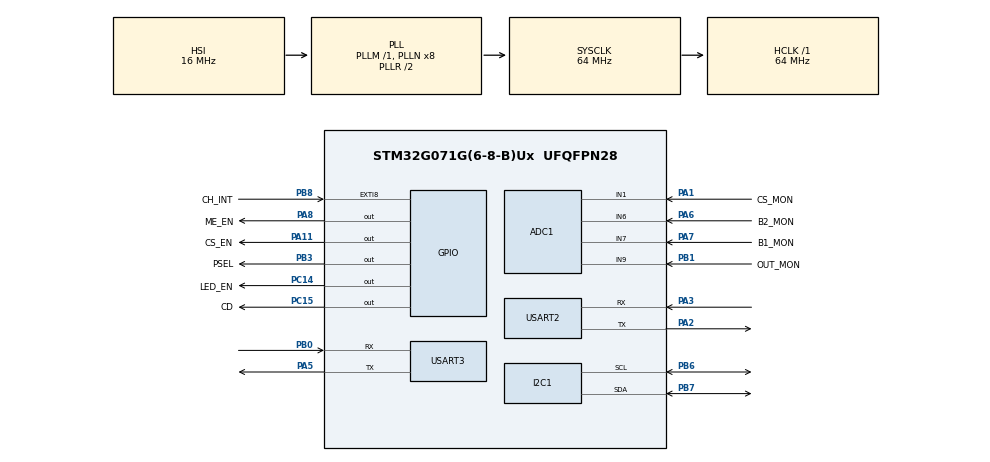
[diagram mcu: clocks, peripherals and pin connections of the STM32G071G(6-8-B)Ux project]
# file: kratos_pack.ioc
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ADC1.Channel-0\#ChannelRegularConversion=ADC_CHANNEL_6
ADC1.NbrOfConversionFlag=1
ADC1.Rank-0\#ChannelRegularConversion=1
ADC1.SamplingTime-0\#ChannelRegularConversion=ADC_SAMPLINGTIME_COMMON_1
ADC1.SelectedChannel=ADC_CHANNEL_1|ADC_CHANNEL_6|ADC_CHANNEL_7|ADC_CHANNEL_9|ADC_CHANNEL_TEMPSENSOR|ADC_CHANNEL_VREFINT
ADC1.master=1
I2C1.Timing=0x10707DBC
Mcu.Family=STM32G0
Mcu.Name=STM32G071G(6-8-B)Ux
Mcu.Package=UFQFPN28
NVIC.USART2_IRQn=true\:0\:0\:false\:false\:true\:true\:true
NVIC.USART3_4_LPUART1_IRQn=true\:0\:0\:false\:false\:true\:true\:true
PA0.GPIO_Label=BOOT
PA0.Mode=SYS_WakeUp0
PA0.Signal=SYS_WKUP1
PA1.GPIO_Label=CS_MON
PA1.Mode=IN1
PA1.Signal=ADC1_IN1
PA11\ [PA9].GPIO_Label=CS_EN
PA11\ [PA9].Signal=GPIO_Output
PA13.Mode=Serial_Wire
PA13.Signal=SYS_SWDIO
PA14-BOOT0.Mode=Serial_Wire
PA14-BOOT0.Signal=SYS_SWCLK
PA2.Mode=Asynchronous
PA2.Signal=USART2_TX
PA3.Mode=Asynchronous
PA3.Signal=USART2_RX
PA4.GPIO_Label=WAKEUP
PA4.Mode=SYS_WakeUp1
PA4.Signal=SYS_WKUP2
PA5.Mode=Asynchronous
PA5.Signal=USART3_TX
PA6.GPIO_Label=B2_MON
PA6.Mode=IN6
PA6.Signal=ADC1_IN6
PA7.GPIO_Label=B1_MON
PA7.Mode=IN7
PA7.Signal=ADC1_IN7
PA8.GPIO_Label=ME_EN
PA8.Signal=GPIO_Output
PB0.Mode=Asynchronous
PB0.Signal=USART3_RX
PB1.GPIO_Label=OUT_MON
PB1.Mode=IN9
PB1.Signal=ADC1_IN9
PB3.GPIO_Label=PSEL
PB3.Signal=GPIO_Output
PB5.GPIO_Label=USD_DET
PB5.Mode=SYS_WakeUp6
PB5.Signal=SYS_WKUP6
PB6.Mode=I2C
PB6.Signal=I2C1_SCL
PB7.Mode=I2C
PB7.Signal=I2C1_SDA
PB8.GPIO_Label=CH_INT
PB8.Signal=GPXTI8
PC14-OSC32_IN\ (PC14).GPIO_Label=LED_EN
PC14-OSC32_IN\ (PC14).Signal=GPIO_Output
PC15-OSC32_OUT\ (PC15).GPIO_Label=CD
PC15-OSC32_OUT\ (PC15).Signal=GPIO_Output
ProjectManager.HeapSize=0x200
ProjectManager.StackSize=0x400
ProjectManager.TargetToolchain=Makefile
RCC.ADCFreq_Value=64000000
RCC.AHBFreq_Value=64000000
RCC.CortexFreq_Value=64000000
RCC.EXTERNAL_CLOCK_VALUE=48000
RCC.HCLKFreq_Value=64000000
RCC.HSE_VALUE=8000000
RCC.HSI_VALUE=16000000
RCC.LSE_VALUE=32768
RCC.SYSCLKFreq_VALUE=64000000
RCC.SYSCLKSource=RCC_SYSCLKSOURCE_PLLCLK
RCC.VCOOutputFreq_Value=128000000
USART2.VirtualMode-Asynchronous=VM_ASYNC
USART3.VirtualMode-Asynchronous=VM_ASYNC
VP_ADC1_TempSens_Input.Mode=IN-TempSens
VP_ADC1_Vref_Input.Mode=IN-Vrefint
VP_SYS_VS_DBSignals.Mode=DisableDeadBatterySignals
VP_TIM2_VS_ClockSourceINT.Mode=Internal
board=custom

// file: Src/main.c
/* USER CODE BEGIN Header */

/**
  ******************************************************************************
  * @file           : main.c
  * @brief          : Main program body
  ******************************************************************************
  * @attention
  *
  * <h2><center>&copy; Copyright (c) 2021 STMicroelectronics.
  * All rights reserved.</center></h2>
  *
  * This software component is licensed by ST under BSD 3-Clause license,
  * the "License"; You may not use this file except in compliance with the
  * License. You may obtain a copy of the License at:
  *                        opensource.org/licenses/BSD-3-Clause
  *
  ******************************************************************************
  */
/* USER CODE END Header */
#include "main.h"

/* USER CODE BEGIN Includes */
#include "stm32g0xx_hal.h"

#include "device/device.hpp"
#include "led/KTD2026.hpp"
#include "apps/i2c_scanner.hpp"
/* USER CODE END Includes */

ADC_HandleTypeDef hadc1;

I2C_HandleTypeDef hi2c1;

TIM_HandleTypeDef htim2;

UART_HandleTypeDef huart2;
UART_HandleTypeDef huart3;

void SystemClock_Config(void);
static void MX_GPIO_Init(void);
static void MX_I2C1_Init(void);
static void MX_USART2_UART_Init(void);
static void MX_USART3_UART_Init(void);
static void MX_ADC1_Init(void);
static void MX_TIM2_Init(void);

int main(void){

    /* MCU Configuration--------------------------------------------------------*/

    /* Reset of all peripherals, Initializes the Flash interface and the Systick. */
    HAL_Init();

    /* Configure the system clock */
    SystemClock_Config();

    /* Initialize all configured peripherals */
    MX_GPIO_Init();
    MX_I2C1_Init();
    MX_USART2_UART_Init();
    MX_USART3_UART_Init();
    MX_ADC1_Init();
    MX_TIM2_Init();
    /* USER CODE BEGIN 2 */
    HAL_Delay(1);

    device()->mcu->UART_2->Send("Hello world\r\n");

    device()->Enable_CLI(device()->mcu->UART_2);
    device()->Enable_Filesystem();
    device()->cli->Enable_filesystem_executable(device()->fs);

    auto app = new I2C_scanner(device()->mcu->I2C_1);

    auto led_enable = new Pin('C', 14);
    led_enable->Set(true);

    auto led = new KTD2026(*(device()->mcu->I2C_1), 0b01100010);
    led->Test();

    /* USER CODE END 2 */

    /* Infinite loop */
    while (1) {

    }
} // main

void SystemClock_Config(void){
    RCC_OscInitTypeDef RCC_OscInitStruct   = { 0 };
    RCC_ClkInitTypeDef RCC_ClkInitStruct   = { 0 };
    RCC_PeriphCLKInitTypeDef PeriphClkInit = { 0 };

    /** Configure the main internal regulator output voltage
    */
    HAL_PWREx_ControlVoltageScaling(PWR_REGULATOR_VOLTAGE_SCALE1);

    /** Initializes the RCC Oscillators according to the specified parameters
    * in the RCC_OscInitTypeDef structure.
    */
    RCC_OscInitStruct.OscillatorType      = RCC_OSCILLATORTYPE_HSI;
    RCC_OscInitStruct.HSIState            = RCC_HSI_ON;
    RCC_OscInitStruct.HSIDiv              = RCC_HSI_DIV1;
    RCC_OscInitStruct.HSICalibrationValue = RCC_HSICALIBRATION_DEFAULT;
    RCC_OscInitStruct.PLL.PLLState        = RCC_PLL_ON;
    RCC_OscInitStruct.PLL.PLLSource       = RCC_PLLSOURCE_HSI;
    RCC_OscInitStruct.PLL.PLLM            = RCC_PLLM_DIV1;
    RCC_OscInitStruct.PLL.PLLN            = 8;
    RCC_OscInitStruct.PLL.PLLP            = RCC_PLLP_DIV2;
    RCC_OscInitStruct.PLL.PLLQ            = RCC_PLLQ_DIV2;
    RCC_OscInitStruct.PLL.PLLR            = RCC_PLLR_DIV2;
    if (HAL_RCC_OscConfig(&RCC_OscInitStruct) != HAL_OK) {
        Error_Handler();
    }

    /** Initializes the CPU, AHB and APB buses clocks
    */
    RCC_ClkInitStruct.ClockType = RCC_CLOCKTYPE_HCLK | RCC_CLOCKTYPE_SYSCLK
      | RCC_CLOCKTYPE_PCLK1;
    RCC_ClkInitStruct.SYSCLKSource   = RCC_SYSCLKSOURCE_PLLCLK;
    RCC_ClkInitStruct.AHBCLKDivider  = RCC_SYSCLK_DIV1;
    RCC_ClkInitStruct.APB1CLKDivider = RCC_HCLK_DIV1;

    if (HAL_RCC_ClockConfig(&RCC_ClkInitStruct, FLASH_LATENCY_2) != HAL_OK) {
        Error_Handler();
    }

    /** Initializes the peripherals clocks
    */
    PeriphClkInit.PeriphClockSelection = RCC_PERIPHCLK_USART2 | RCC_PERIPHCLK_I2C1
      | RCC_PERIPHCLK_ADC;
    PeriphClkInit.Usart2ClockSelection = RCC_USART2CLKSOURCE_PCLK1;
    PeriphClkInit.I2c1ClockSelection   = RCC_I2C1CLKSOURCE_PCLK1;
    PeriphClkInit.AdcClockSelection    = RCC_ADCCLKSOURCE_SYSCLK;
    if (HAL_RCCEx_PeriphCLKConfig(&PeriphClkInit) != HAL_OK) {
        Error_Handler();
    }
} // SystemClock_Config

static void MX_ADC1_Init(void){

    ADC_ChannelConfTypeDef sConfig = { 0 };

    /** Configure the global features of the ADC (Clock, Resolution, Data Alignment and number of conversion)
    */
    hadc1.Instance = ADC1;
    hadc1.Init.ClockPrescaler        = ADC_CLOCK_SYNC_PCLK_DIV4;
    hadc1.Init.Resolution            = ADC_RESOLUTION_12B;
    hadc1.Init.DataAlign             = ADC_DATAALIGN_RIGHT;
    hadc1.Init.ScanConvMode          = ADC_SCAN_DISABLE;
    hadc1.Init.EOCSelection          = ADC_EOC_SINGLE_CONV;
    hadc1.Init.LowPowerAutoWait      = DISABLE;
    hadc1.Init.LowPowerAutoPowerOff  = DISABLE;
    hadc1.Init.ContinuousConvMode    = DISABLE;
    hadc1.Init.NbrOfConversion       = 1;
    hadc1.Init.DiscontinuousConvMode = DISABLE;
    hadc1.Init.ExternalTrigConv      = ADC_SOFTWARE_START;
    hadc1.Init.ExternalTrigConvEdge  = ADC_EXTERNALTRIGCONVEDGE_NONE;
    hadc1.Init.DMAContinuousRequests = DISABLE;
    hadc1.Init.Overrun = ADC_OVR_DATA_PRESERVED;
    hadc1.Init.SamplingTimeCommon1  = ADC_SAMPLETIME_1CYCLE_5;
    hadc1.Init.SamplingTimeCommon2  = ADC_SAMPLETIME_1CYCLE_5;
    hadc1.Init.OversamplingMode     = DISABLE;
    hadc1.Init.TriggerFrequencyMode = ADC_TRIGGER_FREQ_HIGH;
    if (HAL_ADC_Init(&hadc1) != HAL_OK) {
        Error_Handler();
    }

    /** Configure Regular Channel
    */
    sConfig.Channel      = ADC_CHANNEL_6;
    sConfig.Rank         = ADC_REGULAR_RANK_1;
    sConfig.SamplingTime = ADC_SAMPLINGTIME_COMMON_1;
    if (HAL_ADC_ConfigChannel(&hadc1, &sConfig) != HAL_OK) {
        Error_Handler();
    }
} // MX_ADC1_Init

static void MX_I2C1_Init(void){

    hi2c1.Instance              = I2C1;
    hi2c1.Init.Timing           = 0x10707DBC;
    hi2c1.Init.OwnAddress1      = 0;
    hi2c1.Init.AddressingMode   = I2C_ADDRESSINGMODE_7BIT;
    hi2c1.Init.DualAddressMode  = I2C_DUALADDRESS_DISABLE;
    hi2c1.Init.OwnAddress2      = 0;
    hi2c1.Init.OwnAddress2Masks = I2C_OA2_NOMASK;
    hi2c1.Init.GeneralCallMode  = I2C_GENERALCALL_DISABLE;
    hi2c1.Init.NoStretchMode    = I2C_NOSTRETCH_DISABLE;
    if (HAL_I2C_Init(&hi2c1) != HAL_OK) {
        Error_Handler();
    }

    /** Configure Analogue filter
    */
    if (HAL_I2CEx_ConfigAnalogFilter(&hi2c1, I2C_ANALOGFILTER_ENABLE) != HAL_OK) {
        Error_Handler();
    }

    /** Configure Digital filter
    */
    if (HAL_I2CEx_ConfigDigitalFilter(&hi2c1, 0) != HAL_OK) {
        Error_Handler();
    }
} // MX_I2C1_Init

static void MX_TIM2_Init(void){

    TIM_ClockConfigTypeDef sClockSourceConfig = { 0 };
    TIM_MasterConfigTypeDef sMasterConfig     = { 0 };

    htim2.Instance               = TIM2;
    htim2.Init.Prescaler         = 0;
    htim2.Init.CounterMode       = TIM_COUNTERMODE_UP;
    htim2.Init.Period            = 4294967295;
    htim2.Init.ClockDivision     = TIM_CLOCKDIVISION_DIV1;
    htim2.Init.AutoReloadPreload = TIM_AUTORELOAD_PRELOAD_DISABLE;
    if (HAL_TIM_Base_Init(&htim2) != HAL_OK) {
        Error_Handler();
    }
    sClockSourceConfig.ClockSource = TIM_CLOCKSOURCE_INTERNAL;
    if (HAL_TIM_ConfigClockSource(&htim2, &sClockSourceConfig) != HAL_OK) {
        Error_Handler();
    }
    sMasterConfig.MasterOutputTrigger = TIM_TRGO_RESET;
    sMasterConfig.MasterSlaveMode     = TIM_MASTERSLAVEMODE_DISABLE;
    if (HAL_TIMEx_MasterConfigSynchronization(&htim2, &sMasterConfig) != HAL_OK) {
        Error_Handler();
    }
} // MX_TIM2_Init

static void MX_USART2_UART_Init(void){

    huart2.Instance                    = USART2;
    huart2.Init.BaudRate               = 115200;
    huart2.Init.WordLength             = UART_WORDLENGTH_8B;
    huart2.Init.StopBits               = UART_STOPBITS_1;
    huart2.Init.Parity                 = UART_PARITY_NONE;
    huart2.Init.Mode                   = UART_MODE_TX_RX;
    huart2.Init.HwFlowCtl              = UART_HWCONTROL_NONE;
    huart2.Init.OverSampling           = UART_OVERSAMPLING_16;
    huart2.Init.OneBitSampling         = UART_ONE_BIT_SAMPLE_DISABLE;
    huart2.Init.ClockPrescaler         = UART_PRESCALER_DIV1;
    huart2.AdvancedInit.AdvFeatureInit = UART_ADVFEATURE_NO_INIT;
    if (HAL_UART_Init(&huart2) != HAL_OK) {
        Error_Handler();
    }
    if (HAL_UARTEx_SetTxFifoThreshold(&huart2, UART_TXFIFO_THRESHOLD_1_8) != HAL_OK) {
        Error_Handler();
    }
    if (HAL_UARTEx_SetRxFifoThreshold(&huart2, UART_RXFIFO_THRESHOLD_1_8) != HAL_OK) {
        Error_Handler();
    }
    if (HAL_UARTEx_DisableFifoMode(&huart2) != HAL_OK) {
        Error_Handler();
    }
} // MX_USART2_UART_Init

static void MX_USART3_UART_Init(void){

    huart3.Instance                    = USART3;
    huart3.Init.BaudRate               = 115200;
    huart3.Init.WordLength             = UART_WORDLENGTH_8B;
    huart3.Init.StopBits               = UART_STOPBITS_1;
    huart3.Init.Parity                 = UART_PARITY_NONE;
    huart3.Init.Mode                   = UART_MODE_TX_RX;
    huart3.Init.HwFlowCtl              = UART_HWCONTROL_NONE;
    huart3.Init.OverSampling           = UART_OVERSAMPLING_16;
    huart3.Init.OneBitSampling         = UART_ONE_BIT_SAMPLE_DISABLE;
    huart3.Init.ClockPrescaler         = UART_PRESCALER_DIV1;
    huart3.AdvancedInit.AdvFeatureInit = UART_ADVFEATURE_NO_INIT;
    if (HAL_UART_Init(&huart3) != HAL_OK) {
        Error_Handler();
    }
}

static void MX_GPIO_Init(void){
    GPIO_InitTypeDef GPIO_InitStruct = { 0 };

    /* GPIO Ports Clock Enable */
    __HAL_RCC_GPIOC_CLK_ENABLE();
    __HAL_RCC_GPIOA_CLK_ENABLE();
    __HAL_RCC_GPIOB_CLK_ENABLE();

    /*Configure GPIO pin Output Level */
    HAL_GPIO_WritePin(GPIOC, LED_EN_Pin | CD_Pin, GPIO_PIN_RESET);

    /*Configure GPIO pin Output Level */
    HAL_GPIO_WritePin(GPIOA, ME_EN_Pin | CS_EN_Pin, GPIO_PIN_RESET);

    /*Configure GPIO pin Output Level */
    HAL_GPIO_WritePin(PSEL_GPIO_Port, PSEL_Pin, GPIO_PIN_RESET);

    /*Configure GPIO pins : LED_EN_Pin CD_Pin */
    GPIO_InitStruct.Pin   = LED_EN_Pin | CD_Pin;
    GPIO_InitStruct.Mode  = GPIO_MODE_OUTPUT_PP;
    GPIO_InitStruct.Pull  = GPIO_NOPULL;
    GPIO_InitStruct.Speed = GPIO_SPEED_FREQ_LOW;
    HAL_GPIO_Init(GPIOC, &GPIO_InitStruct);

    /*Configure GPIO pins : ME_EN_Pin CS_EN_Pin */
    GPIO_InitStruct.Pin   = ME_EN_Pin | CS_EN_Pin;
    GPIO_InitStruct.Mode  = GPIO_MODE_OUTPUT_PP;
    GPIO_InitStruct.Pull  = GPIO_NOPULL;
    GPIO_InitStruct.Speed = GPIO_SPEED_FREQ_LOW;
    HAL_GPIO_Init(GPIOA, &GPIO_InitStruct);

    /*Configure GPIO pin : PSEL_Pin */
    GPIO_InitStruct.Pin   = PSEL_Pin;
    GPIO_InitStruct.Mode  = GPIO_MODE_OUTPUT_PP;
    GPIO_InitStruct.Pull  = GPIO_NOPULL;
    GPIO_InitStruct.Speed = GPIO_SPEED_FREQ_LOW;
    HAL_GPIO_Init(PSEL_GPIO_Port, &GPIO_InitStruct);

    /*Configure GPIO pin : CH_INT_Pin */
    GPIO_InitStruct.Pin  = CH_INT_Pin;
    GPIO_InitStruct.Mode = GPIO_MODE_IT_RISING;
    GPIO_InitStruct.Pull = GPIO_NOPULL;
    HAL_GPIO_Init(CH_INT_GPIO_Port, &GPIO_InitStruct);
} // MX_GPIO_Init

void Error_Handler(void){
    __disable_irq();
    while (1) { }
}

/************************ (C) COPYRIGHT STMicroelectronics *****END OF FILE****/
